# XMC1400 register map
Vendor: Infineon; File version: 1.0.6 (Reference Manual v1.0)
CPU: CM0 r0p0, little endian, no MPU, no FPU, 2 interrupt priority bits
Registers are 32-bit, read-write, reset 0x0 unless marked. A register's access mark holds for its fields unless they carry their own. Offsets are from the block's base; [hi:lo] are bit positions; {n}, {i} and the like mark numbered series.

## PAU — PAU Unit
Base 0x40000000
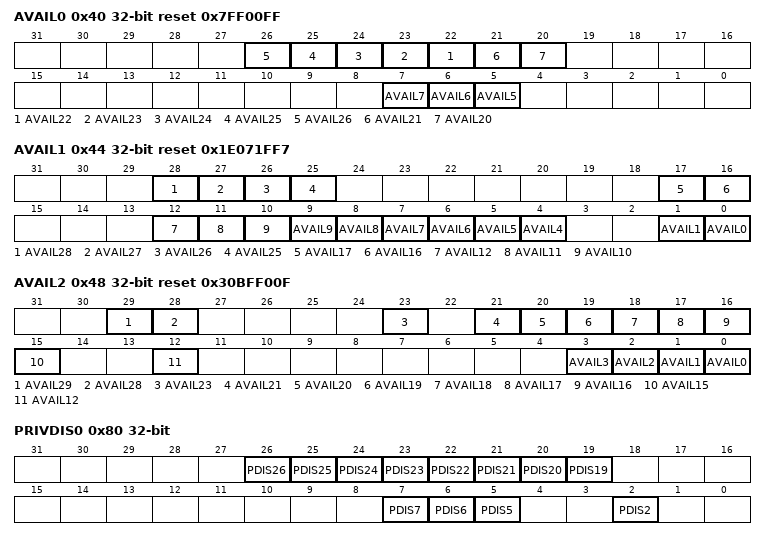
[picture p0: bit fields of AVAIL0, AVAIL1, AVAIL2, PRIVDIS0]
0x40 AVAIL0 ro reset 0x7FF00FF — Peripheral Availability Register 0
  [n] AVAIL{n} (n=22..26) — Port {n-22} Availability Flag
    0=Port {n-22} is not available; 1=Port {n-22} is available
  [21] AVAIL21 — MATH CORDIC Availability Flag
    0=MATH CORDIC is not available; 1=MATH CORDIC is available
  [20] AVAIL20 — MATH Global SFRs and Divider Availability Flag
    0=MATH Global SFRs and Divider are not available; 1=MATH Global SFRs and Divider are available
  [7] AVAIL7 — RAM Block 3 Availability Flag
    0=RAM block 3 is not available; 1=RAM block 3 is available
  [6] AVAIL6 — RAM Block 2 Availability Flag
    0=RAM block 2 is not available; 1=RAM block 2 is available
  [5] AVAIL5 — RAM Block 1 Availability Flag
    0=RAM block 1 is not available; 1=RAM block 1 is available
0x44 AVAIL1 ro reset 0x1E071FF7 — Peripheral Availability Register 1
  [28] AVAIL28 — CCU41 CC43 Availability Flag
    0=CCU41 CC43 is not available; 1=CCU41 CC43 is available
  [27] AVAIL27 — CCU41 CC42 Availability Flag
    0=CCU41 CC42 is not available; 1=CCU41 CC42 is available
  [26] AVAIL26 — CCU41 CC41 Availability Flag
    0=CCU41 CC41 is not available; 1=CCU41 CC41 is available
  [25] AVAIL25 — CCU41 kernel SFRs and CC40 Availability Flag
    0=CCU41 kernel SFRs and CC40 is not available; 1=CCU41 kernel SFRs and CC40 is available
  [17] AVAIL17 — USIC1 Channel 1 Availability Flag
    0=USIC1 Channel 1 is not available; 1=USIC1 Channel 1 is available
  [16] AVAIL16 — USIC1 Channel 0 Availability Flag
    0=USIC1 Channel 0 is not available; 1=USIC1 Channel 0 is available
  [12] AVAIL12 — CCU40 CC43 Availability Flag
    0=CCU40 CC43 is not available; 1=CCU40 CC43 is available
  [11] AVAIL11 — CCU40 CC42 Availability Flag
    0=CCU40 CC42 is not available; 1=CCU40 CC42 is available
  [10] AVAIL10 — CCU40 CC41 Availability Flag
    0=CCU40 CC41 is not available; 1=CCU40 CC41 is available
  [9] AVAIL9 — CCU40 kernel SFRs and CC40 Availability Flag
    0=CCU40 kernel SFRs and CC40 is not available; 1=CCU40 kernel SFRs and CC40 is available
  [8] AVAIL8 — SHS0 Availability Flag
    0=SHS0 is not available; 1=SHS0 is available
  [7] AVAIL7 — VADC0 Group 1 SFRs Availability Flag
    0=VADC0 Group 1 SFRs are not available; 1=VADC0 Group 1 SFRs are available
  [6] AVAIL6 — VADC0 Group 0 SFRs Availability Flag
    0=VADC0 Group 0 SFRs are not available; 1=VADC0 Group 0 SFRs are available
  [5] AVAIL5 — VADC0 Basic SFRs Availability Flag
    0=VADC0 Basic SFRs are not available; 1=VADC0 Basic SFRs are available
  [4] AVAIL4 — PRNG Availability Flag
    0=PRNG is not available; 1=PRNG is available
  [1] AVAIL1 — USIC0 Channel 1 Availability Flag
    0=USIC0 Channel 1 is not available; 1=USIC0 Channel 1 is available
  [0] AVAIL0 — USIC0 Channel 0 Availability Flag
    0=USIC0 Channel 0 is not available; 1=USIC0 Channel 0 is available
0x48 AVAIL2 ro reset 0x30BFF00F — Peripheral Availability Register 2
  [29] AVAIL29 — LEDTS2 Availability Flag
    0=LEDTS2 is not available; 1=LEDTS2 is available
  [28] AVAIL28 — POSIF1 Availability Flag
    0=POSIF1 is not available; 1=POSIF1 is available
  [23] AVAIL23 — MultiCAN Message Object SFRs Availability Flag
    0=MultiCAN message object SFRs are not available; 1=MultiCAN message object SFRs are available
  [21] AVAIL21 — MultiCAN Node 1 Availability Flag
    0=MultiCAN node 1 is not available; 1=MultiCAN node 1 is available
  [20] AVAIL20 — MultiCAN Node 0 and Global SFRs Availability Flag
    0=MultiCAN node 0 and Global SFRs are not available; 1=MultiCAN node 0 and Global SFRs are available
  [19] AVAIL19 — CCU81 CC83 Availability Flag
    0=CCU81 CC83 is not available; 1=CCU81 CC83 is available
  [18] AVAIL18 — CCU81 CC82 Availability Flag
    0=CCU81 CC82 is not available; 1=CCU81 CC82 is available
  [17] AVAIL17 — CCU81 CC81 Availability Flag
    0=CCU81 CC81 is not available; 1=CCU81 CC81 is available
  [16] AVAIL16 — CCU81 kernel SFRs and CC80 Availability Flag
    0=CCU81 kernel SFRs and CC80 are not available; 1=CCU81 kernel SFRs and CC80 are available
  [15] AVAIL15 — BCCU0 Availability Flag
    0=BCCU0 is not available; 1=BCCU0 is available
  [12] AVAIL12 — POSIF0 Availability Flag
    0=POSIF0 is not available; 1=POSIF0 is available
  [3] AVAIL3 — CCU80 CC83 Availability Flag
    0=CCU80 CC83 is not available; 1=CCU80 CC83 is available
  [2] AVAIL2 — CCU80 CC82 Availability Flag
    0=CCU80 CC82 is not available; 1=CCU80 CC82 is available
  [1] AVAIL1 — CCU80 CC81 Availability Flag
    0=CCU80 CC81 is not available; 1=CCU80 CC81 is available
  [0] AVAIL0 — CCU80 kernel SFRs and CC80 Availability Flag
    0=CC80 and CCU80 kernel SFRs are not available; 1=CC80 and CCU80 kernel SFRs are available
0x80 PRIVDIS0 — Peripheral Privilege Access Register 0
  [n] PDIS{n} (n=22..26) — Port {n-22} Privilege Disable Flag
    0=Port {n-22} is accessible; 1=Port {n-22} is not accessible
  [21] PDIS21 — MATH CORDIC Privilege Disable Flag
    0=MATH CORDIC is accessible; 1=MATH CORDIC is not accessible
  [20] PDIS20 — MATH Global SFRs and Divider Privilege Disable Flag
    0=MATH Global SFRs and Divider are accessible; 1=MATH Global SFRs and Divider are not accessible
  [19] PDIS19 — WDT Privilege Disable Flag
    0=WDT is accessible; 1=WDT is not accessible
  [7] PDIS7 — RAM Block 3 Privilege Disable Flag
    0=RAM Block 3 is accessible; 1=RAM Block 3 is not accessible
  [6] PDIS6 — RAM Block 2 Privilege Disable Flag
    0=RAM Block 2 is accessible; 1=RAM Block 2 is not accessible
  [5] PDIS5 — RAM Block 1 Privilege Disable Flag
    0=RAM Block 1 is accessible; 1=RAM Block 1 is not accessible
  [2] PDIS2 — Flash SFRs Privilege Disable Flag
    0=Flash SFRs are accessible; 1=Flash SFRs are not accessible
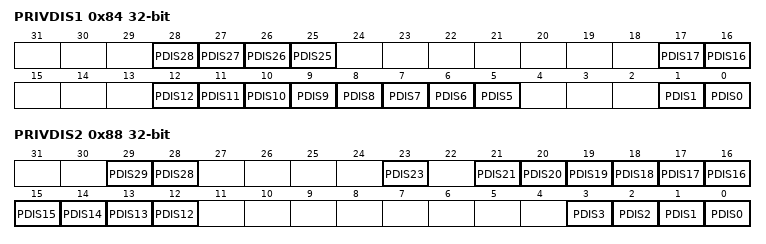
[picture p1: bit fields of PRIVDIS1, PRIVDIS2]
0x84 PRIVDIS1 — Peripheral Privilege Access Register 1
  [28] PDIS28 — CCU41 CC43 Privilege Disable Flag
    0=CCU41 CC43 is accessible; 1=CCU41 CC43 is not accessible
  [27] PDIS27 — CCU41 CC42 Privilege Disable Flag
    0=CCU41 CC42 is accessible; 1=CCU41 CC42 is not accessible
  [26] PDIS26 — CCU41 CC41 Privilege Disable Flag
    0=CCU41 CC41 is accessible; 1=CCU41 CC41 is not accessible
  [25] PDIS25 — CCU41 Kernel SFRs and CC40 Privilege Disable Flag
    0=CCU41 Kernel SFRs and CC40 are accessible; 1=CCU41 Kernel SFRs and CC40 are not accessible
  [17] PDIS17 — USIC1 Channel 1 Privilege Disable Flag
    0=USIC1 Channel 1 is accessible; 1=USIC1 Channel 1 is not accessible
  [16] PDIS16 — USIC1 Channel 0 Privilege Disable Flag
    0=USIC1 Channel 0 is accessible; 1=USIC1 Channel 0 is not accessible
  [12] PDIS12 — CCU40 CC43 Privilege Disable Flag
    0=CCU40 CC43 is accessible; 1=CCU40 CC43 is not accessible
  [11] PDIS11 — CCU40 CC42 Privilege Disable Flag
    0=CCU40 CC42 is accessible; 1=CCU40 CC42 is not accessible
  [10] PDIS10 — CCU40 CC41 Privilege Disable Flag
    0=CCU40 CC41 is accessible; 1=CCU40 CC41 is not accessible
  [9] PDIS9 — CC40 and CCU40 Kernel SFRs Privilege Disable Flag
    0=CC40 and CCU40 Kernel SFRs are accessible; 1=CC40 and CCU40 Kernel SFRs are not accessible
  [8] PDIS8 — SHS0 Privilege Disable Flag
    0=SHS0 is accessible; 1=SHS0 is not accessible
  [7] PDIS7 — VADC0 Group 1 SFRs Privilege Disable Flag
    0=VADC0 Group 1 SFRs are accessible; 1=VADC0 Group 1 SFRs are not accessible
  [6] PDIS6 — VADC0 Group 0 SFRs Privilege Disable Flag
    0=VADC0 Group 0 SFRs are accessible; 1=VADC0 Group 0 SFRs are not accessible
  [5] PDIS5 — VADC0 Basic SFRs Privilege Disable Flag
    0=VADC0 Basic SFRs are accessible; 1=VADC0 Basic SFRs are not accessible
  [1] PDIS1 — USIC0 Channel 1 Privilege Disable Flag
    0=USIC0 Channel 1 is accessible; 1=USIC0 Channel 1 is not accessible
  [0] PDIS0 — USIC0 Channel 0 Privilege Disable Flag
    0=USIC0 Channel 0 is accessible; 1=USIC0 Channel 0 is not accessible
0x88 PRIVDIS2 — Peripheral Privilege Access Register 2
  [29] PDIS29 — LEDTS2 Privilege Disable Flag
    0=LEDTS2 is accessible; 1=LEDTS2 is not accessible
  [28] PDIS28 — POSIF1 Privilege Disable Flag
    0=POSIF1 is accessible; 1=POSIF1 is not accessible
  [23] PDIS23 — MultiCAN Message Object SFRs Privilege Disable Flag
    0=MultiCAN message object SFRs are accessible; 1=MultiCAN message object SFRs are not accessible
  [21] PDIS21 — MultiCAN Node 1 Privilege Disable Flag
    0=MultiCAN node 1 is accessible; 1=MultiCAN node 1 is not accessible
  [20] PDIS20 — MultiCAN Node 0 and Global SFRs Privilege Disable Flag
    0=MultiCAN node 0 and global SFRs are accessible; 1=MultiCAN node 0 and global SFRs are not accessible
  [19] PDIS19 — CCU81 CC83 Privilege Disable Flag
    0=CCU81 CC83 is accessible; 1=CCU81 CC83 is not accessible
  [18] PDIS18 — CCU81 CC82 Privilege Disable Flag
    0=CCU81 CC82 is accessible; 1=CCU81 CC82 is not accessible
  [17] PDIS17 — CCU81 CC81 Privilege Disable Flag
    0=CCU81 CC81 is accessible; 1=CCU81 CC81 is not accessible
  [16] PDIS16 — CCU81 Kernel SFRs and CC80 Privilege Disable Flag
    0=CCU81 Kernel SFRs and CC80 are accessible; 1=CCU81 Kernel SFRs and CC80 are not accessible
  [15] PDIS15 — BCCU0 Privilege Disable Flag
    0=BCCU0 is accessible; 1=BCCU0 is not accessible
  [14] PDIS14 — LEDTS1 Privilege Disable Flag
    0=LEDTS1 is accessible; 1=LEDTS1 is not accessible
  [13] PDIS13 — LEDTS0 Privilege Disable Flag
    0=LEDTS0 is accessible; 1=LEDTS0 is not accessible
  [12] PDIS12 — POSIF0 Privilege Disable Flag
    0=POSIF0 is accessible; 1=POSIF0 is not accessible
  [3] PDIS3 — CCU80 CC83 Privilege Disable Flag
    0=CCU80 CC83 is accessible; 1=CCU80 CC83 is not accessible
  [2] PDIS2 — CCU80 CC82 Privilege Disable Flag
    0=CCU80 CC82 is accessible; 1=CCU80 CC82 is not accessible
  [1] PDIS1 — CCU80 CC81 Privilege Disable Flag
    0=CCU80 CC81 is accessible; 1=CCU80 CC81 is not accessible
  [0] PDIS0 — CC80 and CCU80 Kernel SFRs Privilege Disable Flag
    0=CC80 and CCU80 Kernel SFRs are accessible; 1=CC80 and CCU80 Kernel SFRs are not accessible
0x400 ROMSIZE ro reset 0xB00
  [13:8] ADDR — ROM Size
0x404 FLSIZE ro reset 0x33000 — Flash Size Register
  [17:12] ADDR — Flash Size
0x410 RAM0SIZE ro reset 0x1000
  [12:8] ADDR — RAM0 Size
